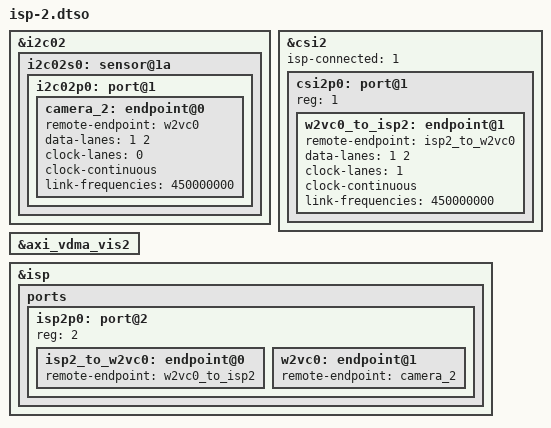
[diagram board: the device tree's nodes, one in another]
// SPDX-License-Identifier: (GPL-2.0+ OR MIT)
/*
 * Copyright (c) 2024 SiMa ai
 */

/dts-v1/;
/plugin/;

&i2c02 {
        i2c02s0: sensor@1a {
                i2c02p0: port@1 {
                        camera_2: endpoint@0 {
                                remote-endpoint = <&w2vc0>;
                                data-lanes = <1 2>;
                                clock-lanes = <0>;
                                clock-continuous;
                                link-frequencies = /bits/ 64 <450000000>;
                        };
                };
        };
};

&csi2 {
		status = "okay";
        isp-connected = <1>;
        csi2p0: port@1 {
                reg = <1>;
                w2vc0_to_isp2: endpoint@1 {
                        remote-endpoint = <&isp2_to_w2vc0>;
                        data-lanes = <1 2>;
                        clock-lanes = <1>;
                        clock-continuous;
                        link-frequencies = /bits/ 64 <450000000>;
                };
        };
};

&axi_vdma_vis2 {
        status = "okay";
};

&isp {
	status = "okay";
	ports {
		#address-cells = <1>;
		#size-cells = <0>;
        isp2p0: port@2 {
				reg = <2>;
                isp2_to_w2vc0: endpoint@0 {
                        remote-endpoint = <&w2vc0_to_isp2>;
                };
                w2vc0: endpoint@1 {
                        remote-endpoint = <&camera_2>;
                };
        };
	};
};
